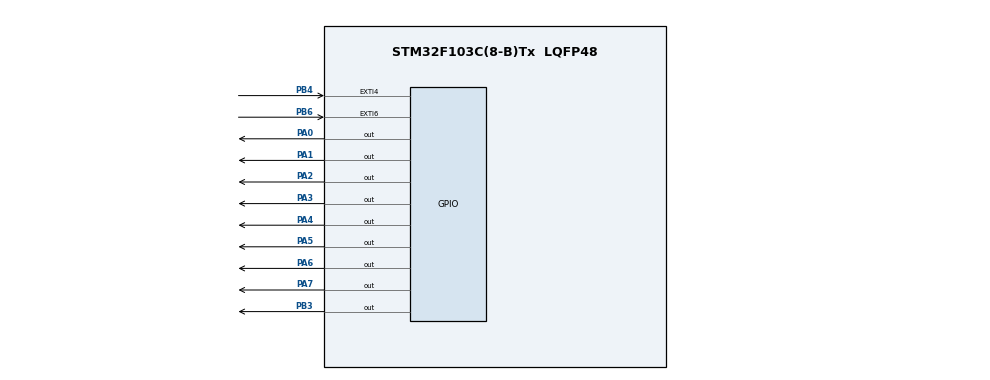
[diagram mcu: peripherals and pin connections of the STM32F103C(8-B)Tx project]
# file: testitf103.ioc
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Mcu.Family=STM32F1
Mcu.Name=STM32F103C(8-B)Tx
Mcu.Package=LQFP48
NVIC.EXTI4_IRQn=true\:0\:0\:false\:true\:true\:1\:true\:true
NVIC.EXTI9_5_IRQn=true\:0\:0\:false\:true\:true\:2\:true\:true
NVIC.PriorityGroup=NVIC_PRIORITYGROUP_4
PA0-WKUP.GPIO_ModeDefaultOutputPP=GPIO_MODE_OUTPUT_PP
PA0-WKUP.PinState=GPIO_PIN_RESET
PA0-WKUP.Signal=GPIO_Output
PA1.PinState=GPIO_PIN_RESET
PA1.Signal=GPIO_Output
PA13.Mode=Serial_Wire
PA13.Signal=SYS_JTMS-SWDIO
PA14.Mode=Serial_Wire
PA14.Signal=SYS_JTCK-SWCLK
PA2.PinState=GPIO_PIN_RESET
PA2.Signal=GPIO_Output
PA3.PinState=GPIO_PIN_RESET
PA3.Signal=GPIO_Output
PA4.PinState=GPIO_PIN_RESET
PA4.Signal=GPIO_Output
PA5.PinState=GPIO_PIN_RESET
PA5.Signal=GPIO_Output
PA6.PinState=GPIO_PIN_RESET
PA6.Signal=GPIO_Output
PA7.PinState=GPIO_PIN_RESET
PA7.Signal=GPIO_Output
PB3.PinState=GPIO_PIN_RESET
PB3.Signal=GPIO_Output
PB4.GPIO_ModeDefaultEXTI=GPIO_MODE_IT_FALLING
PB4.GPIO_PuPd=GPIO_PULLUP
PB4.Signal=GPXTI4
PB6.GPIO_ModeDefaultEXTI=GPIO_MODE_IT_FALLING
PB6.GPIO_PuPd=GPIO_PULLUP
PB6.Signal=GPXTI6
PD0-OSC_IN.Mode=HSE-External-Oscillator
PD0-OSC_IN.Signal=RCC_OSC_IN
PD1-OSC_OUT.Mode=HSE-External-Oscillator
PD1-OSC_OUT.Signal=RCC_OSC_OUT
ProjectManager.HeapSize=0x200
ProjectManager.StackSize=0x400
ProjectManager.TargetToolchain=MDK-ARM V5.27
RCC.APB1Freq_Value=8000000
RCC.APB2Freq_Value=8000000
RCC.SYSCLKSource=RCC_SYSCLKSOURCE_HSE
board=custom

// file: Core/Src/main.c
/* USER CODE BEGIN Header */
/**
  ******************************************************************************
  * @file           : main.c
  * @brief          : Main program body
  ******************************************************************************
  * @attention
  *
  * <h2><center>&copy; Copyright (c) 2020 STMicroelectronics.
  * All rights reserved.</center></h2>
  *
  * This software component is licensed by ST under BSD 3-Clause license,
  * the "License"; You may not use this file except in compliance with the
  * License. You may obtain a copy of the License at:
  *                        opensource.org/licenses/BSD-3-Clause
  *
  ******************************************************************************
  */
/* USER CODE END Header */
#include "main.h"
#include "gpio.h"

/* USER CODE BEGIN Includes */
#include "stm32f1xx_it.h"

/* USER CODE END Includes */

void SystemClock_Config(void);
static void MX_NVIC_Init(void);

int main(void)
{

  /* MCU Configuration--------------------------------------------------------*/

  /* Reset of all peripherals, Initializes the Flash interface and the Systick. */
  HAL_Init();

  /* Configure the system clock */
  SystemClock_Config();

  /* Initialize all configured peripherals */
  MX_GPIO_Init();

  /* Initialize interrupts */
  MX_NVIC_Init();

  /* Infinite loop */
  while (1)
  {

    /* USER CODE BEGIN 3 */
					HAL_GPIO_WritePin(GPIOA, GPIO_PIN_0, GPIO_PIN_SET);

  }
  /* USER CODE END 3 */
}

void SystemClock_Config(void)
{
  RCC_OscInitTypeDef RCC_OscInitStruct = {0};
  RCC_ClkInitTypeDef RCC_ClkInitStruct = {0};

  /** Initializes the RCC Oscillators according to the specified parameters
  * in the RCC_OscInitTypeDef structure.
  */
  RCC_OscInitStruct.OscillatorType = RCC_OSCILLATORTYPE_HSE;
  RCC_OscInitStruct.HSEState = RCC_HSE_ON;
  RCC_OscInitStruct.PLL.PLLState = RCC_PLL_NONE;
  if (HAL_RCC_OscConfig(&RCC_OscInitStruct) != HAL_OK)
  {
    Error_Handler();
  }
  /** Initializes the CPU, AHB and APB buses clocks
  */
  RCC_ClkInitStruct.ClockType = RCC_CLOCKTYPE_HCLK|RCC_CLOCKTYPE_SYSCLK
                              |RCC_CLOCKTYPE_PCLK1|RCC_CLOCKTYPE_PCLK2;
  RCC_ClkInitStruct.SYSCLKSource = RCC_SYSCLKSOURCE_HSE;
  RCC_ClkInitStruct.AHBCLKDivider = RCC_SYSCLK_DIV1;
  RCC_ClkInitStruct.APB1CLKDivider = RCC_HCLK_DIV1;
  RCC_ClkInitStruct.APB2CLKDivider = RCC_HCLK_DIV1;

  if (HAL_RCC_ClockConfig(&RCC_ClkInitStruct, FLASH_LATENCY_0) != HAL_OK)
  {
    Error_Handler();
  }
}

/**
  * @brief NVIC Configuration.
  * @retval None
  */
static void MX_NVIC_Init(void)
{
  /* EXTI4_IRQn interrupt configuration */
  HAL_NVIC_SetPriority(EXTI4_IRQn, 0, 0);
  HAL_NVIC_EnableIRQ(EXTI4_IRQn);
  /* EXTI9_5_IRQn interrupt configuration */
  HAL_NVIC_SetPriority(EXTI9_5_IRQn, 0, 0);
  HAL_NVIC_EnableIRQ(EXTI9_5_IRQn);
}

void Error_Handler(void)
{
}

/************************ (C) COPYRIGHT STMicroelectronics *****END OF FILE****/
